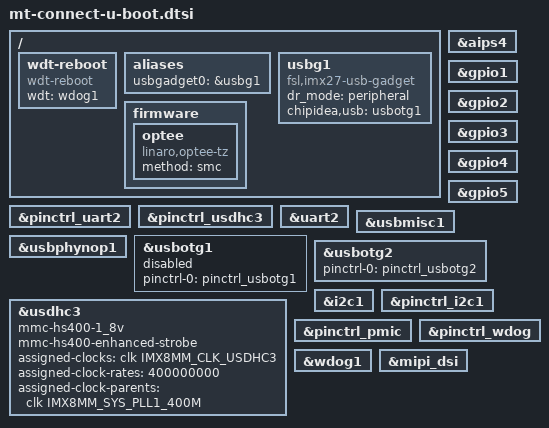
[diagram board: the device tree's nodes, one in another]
// SPDX-License-Identifier: GPL-2.0+
/*
 * Copyright 2024 MultiTracks.com
 */

#include "imx8mm-u-boot.dtsi"

/ {
	wdt-reboot {
		compatible = "wdt-reboot";
		wdt = <&wdog1>;
		bootph-pre-ram;
	};

	aliases {
		usbgadget0 = &usbg1;
	};

	usbg1: usbg1 {
		compatible = "fsl,imx27-usb-gadget";
		dr_mode = "peripheral";
		chipidea,usb = <&usbotg1>;
		status = "okay";
	};

	firmware {
		optee {
			compatible = "linaro,optee-tz";
			method = "smc";
		};
	};
};

&aips4 {
	bootph-pre-ram;
};

&pinctrl_uart2 {
	bootph-pre-ram;
};

&pinctrl_usdhc3 {
	bootph-pre-ram;
};

&gpio1 {
	bootph-pre-ram;
};

&gpio2 {
	bootph-pre-ram;
};

&gpio3 {
	bootph-pre-ram;
};

&gpio4 {
	bootph-pre-ram;
};

&gpio5 {
	bootph-pre-ram;
};

&uart2 {
	bootph-pre-ram;
};

&usbmisc1 {
	bootph-pre-ram;
};

&usbphynop1 {
	bootph-pre-ram;
};

&usbotg1 {
	pinctrl-names = "default";
	pinctrl-0 = <&pinctrl_usbotg1>;
	bootph-pre-ram;
};

&usbotg2 {
	pinctrl-names = "default";
	pinctrl-0 = <&pinctrl_usbotg2>;
	bootph-pre-ram;
};

&usdhc3 {
	bootph-pre-ram;
	mmc-hs400-1_8v;
	mmc-hs400-enhanced-strobe;
	assigned-clocks = <&clk IMX8MM_CLK_USDHC3>;
	assigned-clock-rates = <400000000>;
	assigned-clock-parents = <&clk IMX8MM_SYS_PLL1_400M>;
};

&i2c1 {
	bootph-pre-ram;
};

&pinctrl_i2c1 {
	bootph-pre-ram;
};

&pinctrl_pmic {
	bootph-pre-ram;
};

&pinctrl_wdog {
	bootph-pre-ram;
};

&wdog1 {
	bootph-pre-ram;
};

&usbotg1 {
	status = "enabled";
};

&mipi_dsi {
	/delete-property/ assigned-clocks;
	/delete-property/ assigned-clock-parents;
	/delete-property/ assigned-clock-rates;
};
